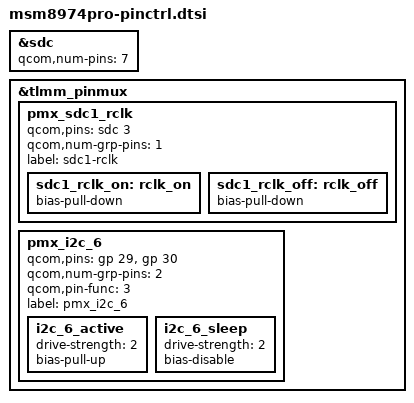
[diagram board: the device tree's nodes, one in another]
/* Copyright (c) 2014, The Linux Foundation. All rights reserved.
 *
 * This program is free software; you can redistribute it and/or modify
 * it under the terms of the GNU General Public License version 2 and
 * only version 2 as published by the Free Software Foundation.
 *
 * This program is distributed in the hope that it will be useful,
 * but WITHOUT ANY WARRANTY; without even the implied warranty of
 * MERCHANTABILITY or FITNESS FOR A PARTICULAR PURPOSE.  See the
 * GNU General Public License for more details.
 */

&sdc {
	/* 0-3 for sdc1 4-6 for sdc2 */
	qcom,num-pins = <7>;
	/* Order of pins */
	/* SDC1: CLK -> 0, CMD -> 1, DATA -> 2, RCLK -> 3 */
	/* SDC2: CLK -> 4, CMD -> 5, DATA -> 6 */
};

&tlmm_pinmux {
	pmx_sdc1_rclk {
		qcom,pins = <&sdc 3>;
		qcom,num-grp-pins = <1>;
		label = "sdc1-rclk";
		sdc1_rclk_on: rclk_on {
			bias-pull-down;
		};
		sdc1_rclk_off: rclk_off {
			bias-pull-down;
		};
	};

	pmx_i2c_6 {
		qcom,pins = <&gp 29>, <&gp 30>; /* SDA, SCL */
		qcom,num-grp-pins = <2>;
		qcom,pin-func = <3>;
		label = "pmx_i2c_6";

		i2c_6_active: i2c_6_active {
			drive-strength = <2>;
			bias-pull-up;
		};

		i2c_6_sleep: i2c_6_sleep {
			drive-strength = <2>;
			bias-disable;
		};
	};
};
